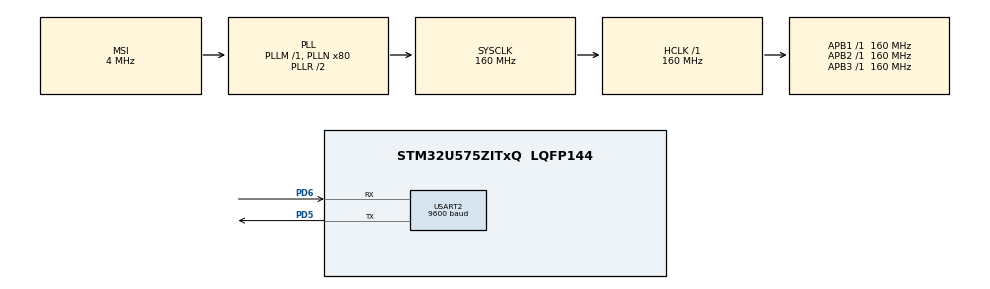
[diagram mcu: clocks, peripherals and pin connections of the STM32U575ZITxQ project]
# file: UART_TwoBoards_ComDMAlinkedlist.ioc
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CORTEX_M33_NS.userName=CORTEX_M33
GPDMA1.LINKALLOCATEDPORT_GPDMACH0=DMA_LINK_ALLOCATED_PORT1
GPDMA1.LINKALLOCATEDPORT_GPDMACH1=DMA_LINK_ALLOCATED_PORT1
GPDMA1.PRIORITY_LL_GPDMACH0=DMA_LOW_PRIORITY_LOW_WEIGHT
GPDMA1.PRIORITY_LL_GPDMACH1=DMA_LOW_PRIORITY_LOW_WEIGHT
Linkedlist.MDMA_Channel0.GP_SW.0.BlkHWRequest=DMA_BREQ_SINGLE_BURST
Linkedlist.MDMA_Channel0.GP_SW.0.DataHandling=NONE
Linkedlist.MDMA_Channel0.GP_SW.0.DataSize=0
Linkedlist.MDMA_Channel0.GP_SW.0.DestBurstLength=1
Linkedlist.MDMA_Channel0.GP_SW.0.DestDataWidth=DMA_DEST_DATAWIDTH_BYTE
Linkedlist.MDMA_Channel0.GP_SW.0.DestInc=DMA_DINC_FIXED
Linkedlist.MDMA_Channel0.GP_SW.0.Direction=DMA_MEMORY_TO_PERIPH
Linkedlist.MDMA_Channel0.GP_SW.0.DstAddress=0
Linkedlist.MDMA_Channel0.GP_SW.0.Instance=MDMA_Channel0
Linkedlist.MDMA_Channel0.GP_SW.0.LL_MASTERDMA=GPDMA
Linkedlist.MDMA_Channel0.GP_SW.0.LL_NAME=UART_Tx_Queue
Linkedlist.MDMA_Channel0.GP_SW.0.LL_TYPE=LINEAR
Linkedlist.MDMA_Channel0.GP_SW.0.NODE_NAME=Node1_tx
Linkedlist.MDMA_Channel0.GP_SW.0.Requestforcodegen=GPDMA1_REQUEST_USART2_TX
Linkedlist.MDMA_Channel0.GP_SW.0.SrcAddress=0
Linkedlist.MDMA_Channel0.GP_SW.0.SrcBurstLength=1
Linkedlist.MDMA_Channel0.GP_SW.0.SrcDataWidth=DMA_SRC_DATAWIDTH_BYTE
Linkedlist.MDMA_Channel0.GP_SW.0.SrcInc=DMA_SINC_INCREMENTED
Linkedlist.MDMA_Channel0.GP_SW.0.TransferAllocatedPortSrc=DMA_SRC_ALLOCATED_PORT0
Linkedlist.MDMA_Channel0.GP_SW.0.TransferEventMode=DMA_TCEM_LAST_LL_ITEM_TRANSFER
Linkedlist.MDMA_Channel0.GP_SW.0.TriggerPolarity=DMA_TRIG_POLARITY_MASKED
Linkedlist.MDMA_Channel0.GP_SW.1.BlkHWRequest=DMA_BREQ_SINGLE_BURST
Linkedlist.MDMA_Channel0.GP_SW.1.DataHandling=NONE
Linkedlist.MDMA_Channel0.GP_SW.1.DataSize=128
Linkedlist.MDMA_Channel0.GP_SW.1.DestBurstLength=1
Linkedlist.MDMA_Channel0.GP_SW.1.DestDataWidth=DMA_DEST_DATAWIDTH_BYTE
Linkedlist.MDMA_Channel0.GP_SW.1.DestInc=DMA_DINC_FIXED
Linkedlist.MDMA_Channel0.GP_SW.1.Direction=DMA_MEMORY_TO_PERIPH
Linkedlist.MDMA_Channel0.GP_SW.1.DstAddress=(uint32_t)&huart2.Instance->TDR
Linkedlist.MDMA_Channel0.GP_SW.1.Instance=MDMA_Channel0
Linkedlist.MDMA_Channel0.GP_SW.1.LL_MASTERDMA=GPDMA
Linkedlist.MDMA_Channel0.GP_SW.1.LL_NAME=UART_Tx_Queue
Linkedlist.MDMA_Channel0.GP_SW.1.LL_TYPE=LINEAR
Linkedlist.MDMA_Channel0.GP_SW.1.NODE_NAME=Node2_tx
Linkedlist.MDMA_Channel0.GP_SW.1.Requestforcodegen=GPDMA1_REQUEST_USART2_TX
Linkedlist.MDMA_Channel0.GP_SW.1.SrcAddress=(uint32_t) aTxBuffer1
Linkedlist.MDMA_Channel0.GP_SW.1.SrcBurstLength=1
Linkedlist.MDMA_Channel0.GP_SW.1.SrcDataWidth=DMA_SRC_DATAWIDTH_BYTE
Linkedlist.MDMA_Channel0.GP_SW.1.SrcInc=DMA_SINC_INCREMENTED
Linkedlist.MDMA_Channel0.GP_SW.1.TransferAllocatedPortSrc=DMA_SRC_ALLOCATED_PORT0
Linkedlist.MDMA_Channel0.GP_SW.1.TransferEventMode=DMA_TCEM_LAST_LL_ITEM_TRANSFER
Linkedlist.MDMA_Channel0.GP_SW.1.TriggerPolarity=DMA_TRIG_POLARITY_MASKED
Linkedlist.MDMA_Channel0.GP_SW.2.BlkHWRequest=DMA_BREQ_SINGLE_BURST
Linkedlist.MDMA_Channel0.GP_SW.2.DataHandling=NONE
Linkedlist.MDMA_Channel0.GP_SW.2.DataSize=128
Linkedlist.MDMA_Channel0.GP_SW.2.DestBurstLength=1
Linkedlist.MDMA_Channel0.GP_SW.2.DestDataWidth=DMA_DEST_DATAWIDTH_BYTE
Linkedlist.MDMA_Channel0.GP_SW.2.DestInc=DMA_DINC_FIXED
Linkedlist.MDMA_Channel0.GP_SW.2.Direction=DMA_MEMORY_TO_PERIPH
Linkedlist.MDMA_Channel0.GP_SW.2.DstAddress=(uint32_t)&huart2.Instance->TDR
Linkedlist.MDMA_Channel0.GP_SW.2.Instance=MDMA_Channel0
Linkedlist.MDMA_Channel0.GP_SW.2.LL_MASTERDMA=GPDMA
Linkedlist.MDMA_Channel0.GP_SW.2.LL_NAME=UART_Tx_Queue
Linkedlist.MDMA_Channel0.GP_SW.2.LL_TYPE=LINEAR
Linkedlist.MDMA_Channel0.GP_SW.2.NODE_NAME=Node3_tx
Linkedlist.MDMA_Channel0.GP_SW.2.Requestforcodegen=GPDMA1_REQUEST_USART2_TX
Linkedlist.MDMA_Channel0.GP_SW.2.SrcAddress=(uint32_t) aTxBuffer2
Linkedlist.MDMA_Channel0.GP_SW.2.SrcBurstLength=1
Linkedlist.MDMA_Channel0.GP_SW.2.SrcDataWidth=DMA_SRC_DATAWIDTH_BYTE
Linkedlist.MDMA_Channel0.GP_SW.2.SrcInc=DMA_SINC_INCREMENTED
Linkedlist.MDMA_Channel0.GP_SW.2.TransferAllocatedPortSrc=DMA_SRC_ALLOCATED_PORT0
Linkedlist.MDMA_Channel0.GP_SW.2.TransferEventMode=DMA_TCEM_LAST_LL_ITEM_TRANSFER
Linkedlist.MDMA_Channel0.GP_SW.2.TriggerPolarity=DMA_TRIG_POLARITY_MASKED
Linkedlist.MDMA_Channel0.Request0=GP_SW
Linkedlist.MDMA_Channel0.Request1=GP_SW
Linkedlist.MDMA_Channel0.Request2=GP_SW
Linkedlist.MDMA_Channel0.RequestsNb=3
Linkedlist.MDMA_Channel1.GP_SW.0.BlkHWRequest=DMA_BREQ_SINGLE_BURST
Linkedlist.MDMA_Channel1.GP_SW.0.DataHandling=NONE
Linkedlist.MDMA_Channel1.GP_SW.0.DataSize=0
Linkedlist.MDMA_Channel1.GP_SW.0.DestBurstLength=1
Linkedlist.MDMA_Channel1.GP_SW.0.DestDataWidth=DMA_DEST_DATAWIDTH_BYTE
Linkedlist.MDMA_Channel1.GP_SW.0.DestInc=DMA_DINC_INCREMENTED
Linkedlist.MDMA_Channel1.GP_SW.0.Direction=DMA_PERIPH_TO_MEMORY
Linkedlist.MDMA_Channel1.GP_SW.0.DstAddress=0
Linkedlist.MDMA_Channel1.GP_SW.0.Instance=MDMA_Channel1
Linkedlist.MDMA_Channel1.GP_SW.0.LL_MASTERDMA=GPDMA
Linkedlist.MDMA_Channel1.GP_SW.0.LL_NAME=UART_Rx_Queue
Linkedlist.MDMA_Channel1.GP_SW.0.LL_TYPE=LINEAR
Linkedlist.MDMA_Channel1.GP_SW.0.NODE_NAME=Node1_rx
Linkedlist.MDMA_Channel1.GP_SW.0.Requestforcodegen=GPDMA1_REQUEST_USART2_RX
Linkedlist.MDMA_Channel1.GP_SW.0.SrcAddress=0
Linkedlist.MDMA_Channel1.GP_SW.0.SrcBurstLength=1
Linkedlist.MDMA_Channel1.GP_SW.0.SrcDataWidth=DMA_SRC_DATAWIDTH_BYTE
Linkedlist.MDMA_Channel1.GP_SW.0.SrcInc=DMA_SINC_FIXED
Linkedlist.MDMA_Channel1.GP_SW.0.TransferAllocatedPortSrc=DMA_SRC_ALLOCATED_PORT0
Linkedlist.MDMA_Channel1.GP_SW.0.TransferEventMode=DMA_TCEM_LAST_LL_ITEM_TRANSFER
Linkedlist.MDMA_Channel1.GP_SW.0.TriggerPolarity=DMA_TRIG_POLARITY_MASKED
Linkedlist.MDMA_Channel1.GP_SW.1.BlkHWRequest=DMA_BREQ_SINGLE_BURST
Linkedlist.MDMA_Channel1.GP_SW.1.DataHandling=NONE
Linkedlist.MDMA_Channel1.GP_SW.1.DataSize=128
Linkedlist.MDMA_Channel1.GP_SW.1.DestBurstLength=1
Linkedlist.MDMA_Channel1.GP_SW.1.DestDataWidth=DMA_DEST_DATAWIDTH_BYTE
Linkedlist.MDMA_Channel1.GP_SW.1.DestInc=DMA_DINC_INCREMENTED
Linkedlist.MDMA_Channel1.GP_SW.1.Direction=DMA_PERIPH_TO_MEMORY
Linkedlist.MDMA_Channel1.GP_SW.1.DstAddress=(uint32_t) aRxBuffer1
Linkedlist.MDMA_Channel1.GP_SW.1.Instance=MDMA_Channel1
Linkedlist.MDMA_Channel1.GP_SW.1.LL_MASTERDMA=GPDMA
Linkedlist.MDMA_Channel1.GP_SW.1.LL_NAME=UART_Rx_Queue
Linkedlist.MDMA_Channel1.GP_SW.1.LL_TYPE=LINEAR
Linkedlist.MDMA_Channel1.GP_SW.1.NODE_NAME=Node2_rx
Linkedlist.MDMA_Channel1.GP_SW.1.Requestforcodegen=GPDMA1_REQUEST_USART2_RX
Linkedlist.MDMA_Channel1.GP_SW.1.SrcAddress=(uint32_t)&huart2.Instance->RDR
Linkedlist.MDMA_Channel1.GP_SW.1.SrcBurstLength=1
Linkedlist.MDMA_Channel1.GP_SW.1.SrcDataWidth=DMA_SRC_DATAWIDTH_BYTE
Linkedlist.MDMA_Channel1.GP_SW.1.SrcInc=DMA_SINC_FIXED
Linkedlist.MDMA_Channel1.GP_SW.1.TransferAllocatedPortSrc=DMA_SRC_ALLOCATED_PORT0
Linkedlist.MDMA_Channel1.GP_SW.1.TransferEventMode=DMA_TCEM_LAST_LL_ITEM_TRANSFER
Linkedlist.MDMA_Channel1.GP_SW.1.TriggerPolarity=DMA_TRIG_POLARITY_MASKED
Linkedlist.MDMA_Channel1.GP_SW.2.BlkHWRequest=DMA_BREQ_SINGLE_BURST
Linkedlist.MDMA_Channel1.GP_SW.2.DataHandling=NONE
Linkedlist.MDMA_Channel1.GP_SW.2.DataSize=128
Linkedlist.MDMA_Channel1.GP_SW.2.DestBurstLength=1
Linkedlist.MDMA_Channel1.GP_SW.2.DestDataWidth=DMA_DEST_DATAWIDTH_BYTE
Linkedlist.MDMA_Channel1.GP_SW.2.DestInc=DMA_DINC_INCREMENTED
Linkedlist.MDMA_Channel1.GP_SW.2.Direction=DMA_PERIPH_TO_MEMORY
Linkedlist.MDMA_Channel1.GP_SW.2.DstAddress=(uint32_t) aRxBuffer2
Linkedlist.MDMA_Channel1.GP_SW.2.Instance=MDMA_Channel1
Linkedlist.MDMA_Channel1.GP_SW.2.LL_MASTERDMA=GPDMA
Linkedlist.MDMA_Channel1.GP_SW.2.LL_NAME=UART_Rx_Queue
Linkedlist.MDMA_Channel1.GP_SW.2.LL_TYPE=LINEAR
Linkedlist.MDMA_Channel1.GP_SW.2.NODE_NAME=Node3_rx
Linkedlist.MDMA_Channel1.GP_SW.2.Requestforcodegen=GPDMA1_REQUEST_USART2_RX
Linkedlist.MDMA_Channel1.GP_SW.2.SrcAddress=(uint32_t)&huart2.Instance->RDR
Linkedlist.MDMA_Channel1.GP_SW.2.SrcBurstLength=1
Linkedlist.MDMA_Channel1.GP_SW.2.SrcDataWidth=DMA_SRC_DATAWIDTH_BYTE
Linkedlist.MDMA_Channel1.GP_SW.2.SrcInc=DMA_SINC_FIXED
Linkedlist.MDMA_Channel1.GP_SW.2.TransferAllocatedPortSrc=DMA_SRC_ALLOCATED_PORT0
Linkedlist.MDMA_Channel1.GP_SW.2.TransferEventMode=DMA_TCEM_LAST_LL_ITEM_TRANSFER
Linkedlist.MDMA_Channel1.GP_SW.2.TriggerPolarity=DMA_TRIG_POLARITY_MASKED
Linkedlist.MDMA_Channel1.Request0=GP_SW
Linkedlist.MDMA_Channel1.Request1=GP_SW
Linkedlist.MDMA_Channel1.Request2=GP_SW
Linkedlist.MDMA_Channel1.RequestsNb=3
Linkedlist.RequestSet0=MDMA_Channel0
Linkedlist.RequestSet1=MDMA_Channel1
Linkedlist.RequestSetsNb=2
Mcu.Family=STM32U5
Mcu.Name=STM32U575ZITxQ
Mcu.Package=LQFP144
NVIC.GPDMA1_Channel0_IRQn=true\:0\:0\:false\:false\:true\:true\:true\:true
NVIC.GPDMA1_Channel1_IRQn=true\:0\:0\:false\:false\:true\:true\:true\:true
NVIC.PriorityGroup=NVIC_PRIORITYGROUP_4
NVIC.USART2_IRQn=true\:0\:0\:false\:false\:true\:true\:true\:true
PD5.GPIO_PuPd=GPIO_NOPULL
PD5.GPIO_Speed=GPIO_SPEED_FREQ_VERY_HIGH
PD5.Mode=Asynchronous
PD5.Signal=USART2_TX
PD6.GPIO_PuPd=GPIO_NOPULL
PD6.GPIO_Speed=GPIO_SPEED_FREQ_VERY_HIGH
PD6.Mode=Asynchronous
PD6.Signal=USART2_RX
PWR.PowerMode=PWR_SMPS_SUPPLY
ProjectManager.HeapSize=0x200
ProjectManager.StackSize=0x400
ProjectManager.TargetToolchain=EWARM V8.32
RCC.ADCFreq_Value=16000000
RCC.AHBFreq_Value=160000000
RCC.APB1Freq_Value=160000000
RCC.APB1TimFreq_Value=160000000
RCC.APB2Freq_Value=160000000
RCC.APB2TimFreq_Value=160000000
RCC.APB3Freq_Value=160000000
RCC.CortexFreq_Value=160000000
RCC.DACCLockSelectionVirtual=RCC_DAC1CLKSOURCE_LSI
RCC.DACCLockSelectionVirtualString=RCC_DAC1CLKSOURCE_LSI
RCC.EPOD_VALUE=4000000
RCC.HCLKFreq_Value=160000000
RCC.HSE_VALUE=16000000
RCC.HSI48_VALUE=48000000
RCC.HSI_VALUE=16000000
RCC.LSE_VALUE=32768
RCC.LSIDIV_VALUE=32000
RCC.MSI_VALUE=4000000
RCC.PLLN=80
RCC.SYSCLKFreq_VALUE=160000000
RCC.SYSCLKSource=RCC_SYSCLKSOURCE_PLLCLK
RCC.USBFreq_Value=48000000
RCC.VCOOutputFreq_Value=320000000
USART2.BaudRate=9600
USART2.VirtualMode-Asynchronous=VM_ASYNC
VP_GPDMA1_VS_GPDMACH0.Mode=LINKEDLIST_GPDMACH0
VP_GPDMA1_VS_GPDMACH1.Mode=LINKEDLIST_GPDMACH1
VP_ICACHE_VS_ICACHE.Mode=DirectMappedCache
VP_LPBAMQUEUE_VS_QUEUE.Mode=QUEUEMODE
VP_LPBAM_VS_SIG1.Mode=SmartRun
VP_LPBAM_VS_SIG4.Mode=LPDMA1
VP_PWR_VS_DBSignals.Mode=DisableDeadBatterySignals
VP_PWR_VS_LPOM.Mode=PowerOptimisation
VP_PWR_VS_SECSignals.Mode=Security/Privilege
board=custom

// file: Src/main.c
/* USER CODE BEGIN Header */
/**
  ******************************************************************************
  * @file           : main.c
  * @brief          : Main program body
  ******************************************************************************
  * @attention
  *
  * Copyright (c) 2021 STMicroelectronics.
  * All rights reserved.
  *
  * This software is licensed under terms that can be found in the LICENSE file
  * in the root directory of this software component.
  * If no LICENSE file comes with this software, it is provided AS-IS.
  *
  ******************************************************************************
  */
/* USER CODE END Header */
#include "main.h"

/* USER CODE BEGIN Includes */
#include "linked_list.h"
/* USER CODE END Includes */

/* USER CODE BEGIN PD */
#define TRANSMITTER_BOARD
/* USER CODE END PD */

DMA_HandleTypeDef handle_GPDMA1_Channel1;
DMA_HandleTypeDef handle_GPDMA1_Channel0;

UART_HandleTypeDef huart2;

/* USER CODE BEGIN PV */
__IO ITStatus UartReady = RESET;
__IO uint32_t UserButtonStatus = 0;  /* set to 1 after User Button interrupt  */
extern DMA_QListTypeDef UART_Tx_Queue;
extern DMA_QListTypeDef UART_Rx_Queue;

/* Buffers used for transmission :
   Size should be a Multiple of cache line size (32 bytes) */
ALIGN_32BYTES (uint8_t aTxBuffer0[]) = "0*****UART_TwoBoards communication based on DMA Linkedlist*****  *****UART_TwoBoards communication based on DMA Linkedlist*****0";
ALIGN_32BYTES (uint8_t aTxBuffer1[]) = "1*****UART_TwoBoards communication based on DMA Linkedlist*****  *****UART_TwoBoards communication based on DMA Linkedlist*****1";
ALIGN_32BYTES (uint8_t aTxBuffer2[]) = "2*****UART_TwoBoards communication based on DMA Linkedlist*****  *****UART_TwoBoards communication based on DMA Linkedlist*****2";

/* Buffer used for reception :
   Size should be a Multiple of cache line size (32 bytes) */
ALIGN_32BYTES (uint8_t aRxBuffer0[RXBUFFERSIZE]);
ALIGN_32BYTES (uint8_t aRxBuffer1[RXBUFFERSIZE]);
ALIGN_32BYTES (uint8_t aRxBuffer2[RXBUFFERSIZE]);
/* USER CODE END PV */

void SystemClock_Config(void);
static void SystemPower_Config(void);
static void MX_GPIO_Init(void);
static void MX_GPDMA1_Init(void);
static void MX_ICACHE_Init(void);
static void MX_USART2_UART_Init(void);
/* USER CODE BEGIN PFP */
static uint16_t Buffercmp(uint8_t* pBuffer1, uint8_t* pBuffer2, uint16_t BufferLength);
/* USER CODE END PFP */

int main(void)
{

  /* USER CODE BEGIN 1 */
  /* STM32U5xx HAL library initialization:
       - Configure the Flash prefetch
       - Configure the Systick to generate an interrupt each 1 msec
       - Set NVIC Group Priority to 3
       - Low Level Initialization
     */
  /* USER CODE END 1 */

  /* MCU Configuration--------------------------------------------------------*/

  /* Reset of all peripherals, Initializes the Flash interface and the Systick. */
  HAL_Init();

  /* Configure the System Power */
  SystemPower_Config();

  /* Configure the system clock */
  SystemClock_Config();

  /* USER CODE BEGIN SysInit */
  /* Configure LED1, LED2 and LED3 */
  BSP_LED_Init(LED1);
  BSP_LED_Init(LED2);
  BSP_LED_Init(LED3);
  /* USER CODE END SysInit */

  /* Initialize all configured peripherals */
  MX_GPIO_Init();
  MX_GPDMA1_Init();
  MX_ICACHE_Init();
  MX_USART2_UART_Init();
  /* USER CODE BEGIN 2 */

  MX_UART_Tx_Queue_Config();
  MX_UART_Rx_Queue_Config();
  /* Link UART queue to DMA channel */
  HAL_DMAEx_List_LinkQ(&handle_GPDMA1_Channel0, &UART_Tx_Queue);

  /* Associate the initialized GPDMA handle to the UART handle */
  __HAL_LINKDMA(&huart2, hdmatx, handle_GPDMA1_Channel0);

  /* Link UART queue to DMA channel */
  HAL_DMAEx_List_LinkQ(&handle_GPDMA1_Channel1, &UART_Rx_Queue);

  /* Associate the initialized GPDMA handle to the UART handle */
  __HAL_LINKDMA(&huart2, hdmarx, handle_GPDMA1_Channel1);

#ifdef TRANSMITTER_BOARD

  /* Configure User push-button in Interrupt mode */
  BSP_PB_Init(BUTTON_USER, BUTTON_MODE_EXTI);

  /* Wait for User push-button press before starting the Communication.
     In the meantime, LED2 is blinking */
  while(UserButtonStatus == 0)
  {
      /* Toggle LED2*/
      BSP_LED_Toggle(LED2);
      HAL_Delay(100);
  }

  BSP_LED_Off(LED2);

  /* The board sends the message and expects to receive it back */

  /*##-2- Start the transmission process #####################################*/
  /* While the UART in reception process, user can transmit data through
     "aTxBuffer" buffer */
  if(HAL_UART_Transmit_DMA(&huart2, (uint8_t*)aTxBuffer0, TXBUFFERSIZE)!= HAL_OK)
  {
    Error_Handler();
  }

  /*##-3- Wait for the end of the transfer ###################################*/
  while (UartReady != SET)
  {
  }

  /* Reset transmission flag */
  UartReady = RESET;

  /*##-4- Put UART peripheral in reception process ###########################*/
  if(HAL_UART_Receive_DMA(&huart2, (uint8_t *)aRxBuffer0, RXBUFFERSIZE) != HAL_OK)
  {
    Error_Handler();
  }

#else

  /* The board receives the message and sends it back */

  /*##-2- Put UART peripheral in reception process ###########################*/
  if(HAL_UART_Receive_DMA(&huart2, (uint8_t *)aRxBuffer0, RXBUFFERSIZE) != HAL_OK)
  {
    Error_Handler();
  }

  /*##-3- Wait for the end of the transfer ###################################*/
  /* While waiting for message to come from the other board, LED2 is
     blinking according to the following pattern: a double flash every half-second */
  while (UartReady != SET)
  {
      BSP_LED_On(LED2);
      HAL_Delay(100);
      BSP_LED_Off(LED2);
      HAL_Delay(100);
      BSP_LED_On(LED2);
      HAL_Delay(100);
      BSP_LED_Off(LED2);
      HAL_Delay(500);
  }

  /* Reset transmission flag */
  UartReady = RESET;
  BSP_LED_Off(LED2);

  /*##-4- Start the transmission process #####################################*/
  if(HAL_UART_Transmit_DMA(&huart2, (uint8_t*)aTxBuffer0, TXBUFFERSIZE)!= HAL_OK)
  {
    Error_Handler();
  }

#endif /* TRANSMITTER_BOARD */

  /*##-5- Wait for the end of the transfer ###################################*/
  while (UartReady != SET)
  {
  }

  /* Reset transmission flag */
  UartReady = RESET;

  /*##-6- Compare the sent and received buffers ##############################*/
  if((Buffercmp((uint8_t*)aTxBuffer0,(uint8_t*)aRxBuffer0,RXBUFFERSIZE) != 0) ||\
     (Buffercmp((uint8_t*)aTxBuffer1,(uint8_t*)aRxBuffer1,RXBUFFERSIZE) != 0) ||\
     (Buffercmp((uint8_t*)aTxBuffer2,(uint8_t*)aRxBuffer2,RXBUFFERSIZE) != 0))
  {
    Error_Handler();
  }

  /* Turn on LED1 if test passes then enter infinite loop */
  BSP_LED_On(LED1);

  /* USER CODE END 2 */

  /* Infinite loop */
  while (1)
  {

  }
}

void SystemClock_Config(void)
{
  RCC_OscInitTypeDef RCC_OscInitStruct = {0};
  RCC_ClkInitTypeDef RCC_ClkInitStruct = {0};

  /** Configure the main internal regulator output voltage
  */
  if (HAL_PWREx_ControlVoltageScaling(PWR_REGULATOR_VOLTAGE_SCALE1) != HAL_OK)
  {
    Error_Handler();
  }

  /** Initializes the CPU, AHB and APB buses clocks
  */
  RCC_OscInitStruct.OscillatorType = RCC_OSCILLATORTYPE_MSI;
  RCC_OscInitStruct.MSIState = RCC_MSI_ON;
  RCC_OscInitStruct.MSICalibrationValue = RCC_MSICALIBRATION_DEFAULT;
  RCC_OscInitStruct.MSIClockRange = RCC_MSIRANGE_4;
  RCC_OscInitStruct.PLL.PLLState = RCC_PLL_ON;
  RCC_OscInitStruct.PLL.PLLSource = RCC_PLLSOURCE_MSI;
  RCC_OscInitStruct.PLL.PLLMBOOST = RCC_PLLMBOOST_DIV1;
  RCC_OscInitStruct.PLL.PLLM = 1;
  RCC_OscInitStruct.PLL.PLLN = 80;
  RCC_OscInitStruct.PLL.PLLP = 2;
  RCC_OscInitStruct.PLL.PLLQ = 2;
  RCC_OscInitStruct.PLL.PLLR = 2;
  RCC_OscInitStruct.PLL.PLLRGE = RCC_PLLVCIRANGE_0;
  RCC_OscInitStruct.PLL.PLLFRACN = 0;
  if (HAL_RCC_OscConfig(&RCC_OscInitStruct) != HAL_OK)
  {
    Error_Handler();
  }

  /** Initializes the CPU, AHB and APB buses clocks
  */
  RCC_ClkInitStruct.ClockType = RCC_CLOCKTYPE_HCLK|RCC_CLOCKTYPE_SYSCLK
                              |RCC_CLOCKTYPE_PCLK1|RCC_CLOCKTYPE_PCLK2
                              |RCC_CLOCKTYPE_PCLK3;
  RCC_ClkInitStruct.SYSCLKSource = RCC_SYSCLKSOURCE_PLLCLK;
  RCC_ClkInitStruct.AHBCLKDivider = RCC_SYSCLK_DIV1;
  RCC_ClkInitStruct.APB1CLKDivider = RCC_HCLK_DIV1;
  RCC_ClkInitStruct.APB2CLKDivider = RCC_HCLK_DIV1;
  RCC_ClkInitStruct.APB3CLKDivider = RCC_HCLK_DIV1;

  if (HAL_RCC_ClockConfig(&RCC_ClkInitStruct, FLASH_LATENCY_4) != HAL_OK)
  {
    Error_Handler();
  }
}

/**
  * @brief Power Configuration
  * @retval None
  */
static void SystemPower_Config(void)
{

  /*
   * Disable the internal Pull-Up in Dead Battery pins of UCPD peripheral
   */
  HAL_PWREx_DisableUCPDDeadBattery();

  /*
   * Switch to SMPS regulator instead of LDO
   */
  if (HAL_PWREx_ConfigSupply(PWR_SMPS_SUPPLY) != HAL_OK)
  {
    Error_Handler();
  }
}

static void MX_GPDMA1_Init(void)
{

  /* Peripheral clock enable */
  __HAL_RCC_GPDMA1_CLK_ENABLE();

  /* GPDMA1 interrupt Init */
    HAL_NVIC_SetPriority(GPDMA1_Channel0_IRQn, 0, 0);
    HAL_NVIC_EnableIRQ(GPDMA1_Channel0_IRQn);
    HAL_NVIC_SetPriority(GPDMA1_Channel1_IRQn, 0, 0);
    HAL_NVIC_EnableIRQ(GPDMA1_Channel1_IRQn);

  handle_GPDMA1_Channel1.Instance = GPDMA1_Channel1;
  handle_GPDMA1_Channel1.InitLinkedList.Priority = DMA_LOW_PRIORITY_LOW_WEIGHT;
  handle_GPDMA1_Channel1.InitLinkedList.LinkStepMode = DMA_LSM_FULL_EXECUTION;
  handle_GPDMA1_Channel1.InitLinkedList.LinkAllocatedPort = DMA_LINK_ALLOCATED_PORT1;
  handle_GPDMA1_Channel1.InitLinkedList.TransferEventMode = DMA_TCEM_LAST_LL_ITEM_TRANSFER;
  handle_GPDMA1_Channel1.InitLinkedList.LinkedListMode = DMA_LINKEDLIST_NORMAL;
  if (HAL_DMAEx_List_Init(&handle_GPDMA1_Channel1) != HAL_OK)
  {
    Error_Handler();
  }
  if (HAL_DMA_ConfigChannelAttributes(&handle_GPDMA1_Channel1, DMA_CHANNEL_NPRIV) != HAL_OK)
  {
    Error_Handler();
  }
  handle_GPDMA1_Channel0.Instance = GPDMA1_Channel0;
  handle_GPDMA1_Channel0.InitLinkedList.Priority = DMA_LOW_PRIORITY_LOW_WEIGHT;
  handle_GPDMA1_Channel0.InitLinkedList.LinkStepMode = DMA_LSM_FULL_EXECUTION;
  handle_GPDMA1_Channel0.InitLinkedList.LinkAllocatedPort = DMA_LINK_ALLOCATED_PORT1;
  handle_GPDMA1_Channel0.InitLinkedList.TransferEventMode = DMA_TCEM_LAST_LL_ITEM_TRANSFER;
  handle_GPDMA1_Channel0.InitLinkedList.LinkedListMode = DMA_LINKEDLIST_NORMAL;
  if (HAL_DMAEx_List_Init(&handle_GPDMA1_Channel0) != HAL_OK)
  {
    Error_Handler();
  }
  if (HAL_DMA_ConfigChannelAttributes(&handle_GPDMA1_Channel0, DMA_CHANNEL_NPRIV) != HAL_OK)
  {
    Error_Handler();
  }

}

static void MX_ICACHE_Init(void)
{

  /** Enable instruction cache in 1-way (direct mapped cache)
  */
  if (HAL_ICACHE_ConfigAssociativityMode(ICACHE_1WAY) != HAL_OK)
  {
    Error_Handler();
  }
  if (HAL_ICACHE_Enable() != HAL_OK)
  {
    Error_Handler();
  }

}

static void MX_USART2_UART_Init(void)
{

  huart2.Instance = USART2;
  huart2.Init.BaudRate = 9600;
  huart2.Init.WordLength = UART_WORDLENGTH_8B;
  huart2.Init.StopBits = UART_STOPBITS_1;
  huart2.Init.Parity = UART_PARITY_NONE;
  huart2.Init.Mode = UART_MODE_TX_RX;
  huart2.Init.HwFlowCtl = UART_HWCONTROL_NONE;
  huart2.Init.OverSampling = UART_OVERSAMPLING_16;
  huart2.Init.OneBitSampling = UART_ONE_BIT_SAMPLE_DISABLE;
  huart2.Init.ClockPrescaler = UART_PRESCALER_DIV1;
  huart2.AdvancedInit.AdvFeatureInit = UART_ADVFEATURE_NO_INIT;
  if (HAL_UART_Init(&huart2) != HAL_OK)
  {
    Error_Handler();
  }
  if (HAL_UARTEx_SetTxFifoThreshold(&huart2, UART_TXFIFO_THRESHOLD_1_8) != HAL_OK)
  {
    Error_Handler();
  }
  if (HAL_UARTEx_SetRxFifoThreshold(&huart2, UART_RXFIFO_THRESHOLD_1_8) != HAL_OK)
  {
    Error_Handler();
  }
  if (HAL_UARTEx_DisableFifoMode(&huart2) != HAL_OK)
  {
    Error_Handler();
  }

}

static void MX_GPIO_Init(void)
{

  /* GPIO Ports Clock Enable */
  __HAL_RCC_GPIOD_CLK_ENABLE();

}

/* USER CODE BEGIN 4 */
/**
  * @brief  Tx Transfer completed callback
  * @param  UartHandle: UART handle.
  * @note   This example shows a simple way to report end of DMA Tx transfer, and
  *         you can add your own implementation.
  * @retval None
  */
void HAL_UART_TxCpltCallback(UART_HandleTypeDef *UartHandle)
{
  /* Set transmission flag: transfer complete */
  UartReady = SET;

#ifdef TRANSMITTER_BOARD
  /* Turn LED1 on: Transfer in transmission process is correct */
  BSP_LED_On(LED1);
#else
	/* Turn LED1 off: Transfer in transmission process is correct */
  BSP_LED_Off(LED1);
#endif  /* TRANSMITTER_BOARD */

}

/**
  * @brief  Rx Transfer completed callback
  * @param  UartHandle: UART handle
  * @note   This example shows a simple way to report end of DMA Rx transfer, and
  *         you can add your own implementation.
  * @retval None
  */
void HAL_UART_RxCpltCallback(UART_HandleTypeDef *UartHandle)
{
  /* Set transmission flag: transfer complete */
  UartReady = SET;

#ifdef TRANSMITTER_BOARD
  /* Turn LED1 off: Transfer in reception process is correct */
  BSP_LED_Off(LED1);
#else
  /* Turn LED1 on: Transfer in reception process is correct */
  BSP_LED_On(LED1);
#endif  /* TRANSMITTER_BOARD */

}

/**
  * @brief  UART error callbacks
  * @param  UartHandle: UART handle
  * @note   This example shows a simple way to report transfer error, and you can
  *         add your own implementation.
  * @retval None
  */
void HAL_UART_ErrorCallback(UART_HandleTypeDef *UartHandle)
{
    Error_Handler();
}

/**
  * @brief EXTI line detection callbacks
  * @param GPIO_Pin: Specifies the pins connected EXTI line
  * @retval None
  */
void BSP_PB_Callback(Button_TypeDef Button)
{
  if(Button == BUTTON_USER)
  {
    UserButtonStatus = 1;
  }
}

/**
  * @brief  Compares two buffers.
  * @param  pBuffer1, pBuffer2: buffers to be compared.
  * @param  BufferLength: buffer's length
  * @retval 0  : pBuffer1 identical to pBuffer2
  *         >0 : pBuffer1 differs from pBuffer2
  */
static uint16_t Buffercmp(uint8_t* pBuffer1, uint8_t* pBuffer2, uint16_t BufferLength)
{
  while (BufferLength--)
  {
    if ((*pBuffer1) != *pBuffer2)
    {
      return BufferLength;
    }
    pBuffer1++;
    pBuffer2++;
  }

  return 0;
}
/* USER CODE END 4 */

void Error_Handler(void)
{
  /* USER CODE BEGIN Error_Handler_Debug */
  /* Turn LED3 on */
  BSP_LED_On(LED3);
  __disable_irq();
  while (1)
  {
  }
  /* USER CODE END Error_Handler_Debug */
}
